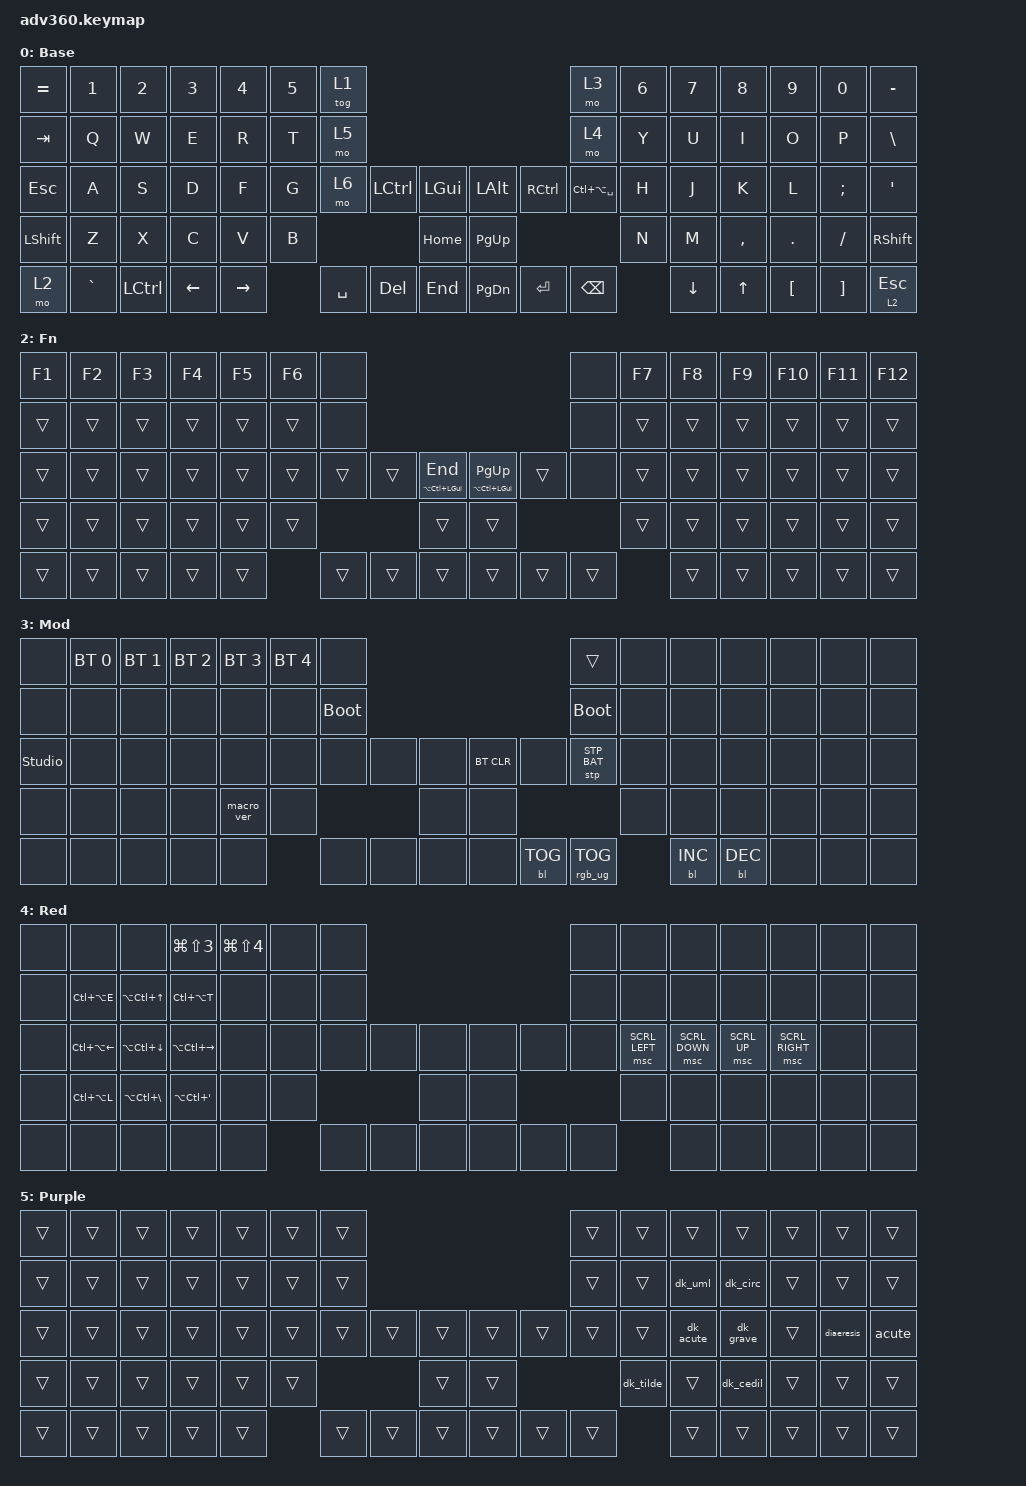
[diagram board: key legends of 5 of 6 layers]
#include <dt-bindings/zmk/stp.h>
#include <behaviors.dtsi>
#include <dt-bindings/zmk/backlight.h>
#include <dt-bindings/zmk/bt.h>
#include <dt-bindings/zmk/keys.h>
#include <dt-bindings/zmk/pointing.h>
#include <dt-bindings/zmk/rgb.h>

#define BASE  0
#define ISO   1
#define FN    2
#define Mod   3
#define MacOs 4

/ {
    behaviors {
        #include "macros.dtsi"
        #include "version.dtsi"

        rpi: require_prior_idle {
            compatible = "zmk,behavior-hold-tap";
            #binding-cells = <2>;
            flavor = "tap-preferred";
            tapping-term-ms = <200>;
            quick-tap-ms = <200>;
            require-prior-idle-ms = <1>;
            bindings = <&kp>, <&kp>;
        };

        hm: homerow_mods {
            compatible = "zmk,behavior-hold-tap";
            label = "HOMEROW_MODS";
            #binding-cells = <2>;
            tapping-term-ms = <200>;
            quick_tap_ms = <175>;
            flavor = "tap-preferred";
            bindings = <&kp>, <&kp>;
        };

        cmt: mod_toggler {
            compatible = "zmk,behavior-hold-tap";
            label = "MOD_TOGGLER";
            #binding-cells = <2>;
            tapping-term-ms = <200>;
            quick_tap_ms = <175>;
            flavor = "tap-preferred";
            bindings = <&mo>, <&kp>;
        };
    };

    keymap {
        compatible = "zmk,keymap";

        default_layer {
            display-name = "Base";
            bindings = <
&kp EQUAL  &kp N1     &kp N2     &kp N3    &kp N4     &kp N5  &tog 1                                                         &mo 3              &kp N6  &kp N7    &kp N8     &kp N9    &kp N0    &kp MINUS
&kp TAB    &kp Q      &kp W      &kp E     &kp R      &kp T   &mo 5                                                          &mo 4              &kp Y   &kp U     &kp I      &kp O     &kp P     &kp BSLH
&kp ESC    &kp A      &kp S      &kp D     &kp F      &kp G   &mo 6      &kp LCTRL   &kp LGUI      &kp LALT       &kp RCTRL  &kp LC(LA(SPACE))  &kp H   &kp J     &kp K      &kp L     &kp SEMI  &kp SQT
&kp LSHFT  &kp Z      &kp X      &kp C     &kp V      &kp B                          &kp HOME      &kp PG_UP                                    &kp N   &kp M     &kp COMMA  &kp DOT   &kp FSLH  &kp RSHFT
&mo 2      &kp GRAVE  &kp LCTRL  &kp LEFT  &kp RIGHT          &kp SPACE  &kp DELETE  &kp END       &kp PAGE_DOWN  &kp ENTER  &kp BSPC                   &kp DOWN  &kp UP     &kp LBKT  &kp RBKT  &cmt 2 ESC
            >;
        };

        iso {
            display-name = "Iso";
            bindings = <
&trans  &trans    &trans  &trans  &trans  &trans  &trans                                      &trans  &trans  &trans  &trans  &trans  &trans  &trans
&trans  &trans    &trans  &trans  &trans  &trans  &trans                                      &trans  &trans  &trans  &trans  &trans  &trans  &kp LBKT
&trans  &trans    &trans  &trans  &trans  &trans  &trans  &trans  &trans      &trans  &trans  &trans  &trans  &trans  &trans  &trans  &trans  &trans
&trans  &trans    &trans  &trans  &trans  &trans                  &trans      &trans                  &trans  &trans  &trans  &trans  &trans  &trans
&trans  &kp BSLH  &trans  &trans  &trans          &trans  &trans  &trans      &trans  &trans  &trans          &trans  &trans  &trans  &trans
            >;
        };

        fn {
            display-name = "Fn";
            bindings = <
&kp F1  &kp F2  &kp F3  &kp F4  &kp F5  &kp F6  &none                                                                       &none   &kp F7  &kp F8  &kp F9  &kp F10  &kp F11  &kp F12
&trans  &trans  &trans  &trans  &trans  &trans  &none                                                                       &none   &trans  &trans  &trans  &trans   &trans   &trans
&trans  &trans  &trans  &trans  &trans  &trans  &trans  &trans  &mt LA(LC(LGUI)) END      &mt LA(LC(LGUI)) PAGE_UP  &trans  &none   &trans  &trans  &trans  &trans   &trans   &trans
&trans  &trans  &trans  &trans  &trans  &trans                  &trans                    &trans                                    &trans  &trans  &trans  &trans   &trans   &trans
&trans  &trans  &trans  &trans  &trans          &trans  &trans  &trans                    &trans                    &trans  &trans          &trans  &trans  &trans   &trans   &trans
            >;
        };

        mod {
            display-name = "Mod";
            bindings = <
&none           &bt BT_SEL 0  &bt BT_SEL 1  &bt BT_SEL 2  &bt BT_SEL 3  &bt BT_SEL 4  &none                                                  &trans           &none  &none       &none       &none  &none  &none
&none           &none         &none         &none         &none         &none         &bootloader                                            &bootloader      &none  &none       &none       &none  &none  &none
&studio_unlock  &none         &none         &none         &none         &none         &none        &none  &none      &bt BT_CLR  &none       &stp STP_BAT     &none  &none       &none       &none  &none  &none
&none           &none         &none         &none         &macro_ver    &none                             &none      &none                                    &none  &none       &none       &none  &none  &none
&none           &none         &none         &none         &none                       &none        &none  &none      &none       &bl BL_TOG  &rgb_ug RGB_TOG         &bl BL_INC  &bl BL_DEC  &none  &none  &none
            >;
        };

        macos {
            display-name = "Red";
            bindings = <
&none  &none             &none             &kp LG(LS(N3))     &kp LG(LS(N4))  &none  &none                                  &none  &none           &none           &none         &none            &none  &none
&none  &kp LC(LA(E))     &kp LA(LC(UP))    &kp LC(LA(T))      &none           &none  &none                                  &none  &none           &none           &none         &none            &none  &none
&none  &kp LC(LA(LEFT))  &kp LA(LC(DOWN))  &kp LA(LC(RIGHT))  &none           &none  &none  &none  &none      &none  &none  &none  &msc SCRL_LEFT  &msc SCRL_DOWN  &msc SCRL_UP  &msc SCRL_RIGHT  &none  &none
&none  &kp LC(LA(L))     &kp LA(LC(BSLH))  &kp LA(LC(SQT))    &none           &none                &none      &none                &none           &none           &none         &none            &none  &none
&none  &none             &none             &none              &none                  &none  &none  &none      &none  &none  &none                  &none           &none         &none            &none  &none
            >;
        };

        extra2 {
            display-name = "Purple";
            bindings = <
&trans  &trans  &trans  &trans  &trans  &trans  &trans                                      &trans  &trans     &trans     &trans     &trans  &trans      &trans
&trans  &trans  &trans  &trans  &trans  &trans  &trans                                      &trans  &trans     &dk_uml    &dk_circ   &trans  &trans      &trans
&trans  &trans  &trans  &trans  &trans  &trans  &trans  &trans  &trans      &trans  &trans  &trans  &trans     &dk_acute  &dk_grave  &trans  &diaeresis  &acute
&trans  &trans  &trans  &trans  &trans  &trans                  &trans      &trans                  &dk_tilde  &trans     &dk_cedil  &trans  &trans      &trans
&trans  &trans  &trans  &trans  &trans          &trans  &trans  &trans      &trans  &trans  &trans             &trans     &trans     &trans  &trans      &trans
            >;
        };

        extra3 {
            display-name = "Cyan";
            status = "reserved";
        };

        extra4 {
            display-name = "Yellow";
            status = "reserved";
        };
    };
};
